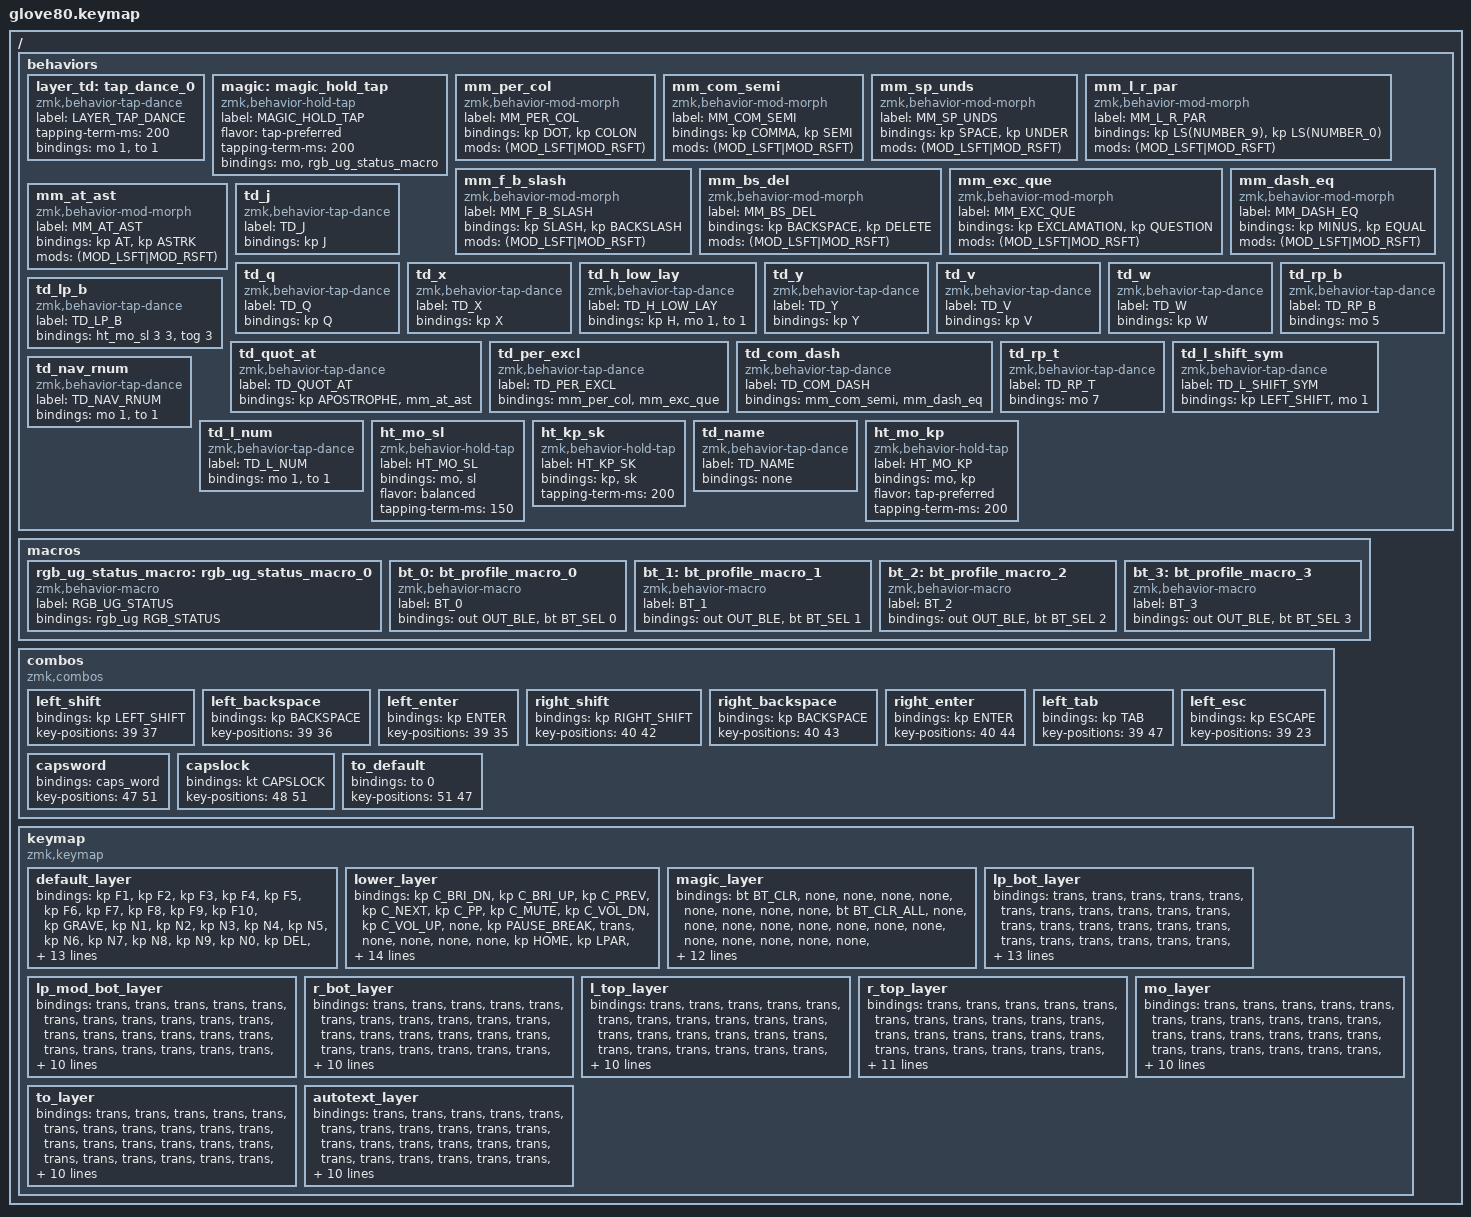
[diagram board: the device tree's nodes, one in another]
/*
 * Copyright (c) 2020 The ZMK Contributors
 *
 * SPDX-License-Identifier: MIT
 */

#include <behaviors.dtsi>
#include <dt-bindings/zmk/bt.h>
#include <dt-bindings/zmk/keys.h>
#include <dt-bindings/zmk/keys.h>
#include <dt-bindings/zmk/outputs.h>
#include <dt-bindings/zmk/rgb.h>

#define HYPER LC(LS(LG(LALT)))

// layers

#define DEFAULT 0
#define LOWER 1
#define MAGIC 2
#define FACTORY_TEST 3

/ {
    behaviors {
        // For the "layer" key, it'd nice to be able to use it as either a shift or a toggle.
        // Configure it as a tap dance, so the first tap (or hold) is a &mo and the second tap is a &to

        layer_td: tap_dance_0 {
            compatible = "zmk,behavior-tap-dance";
            label = "LAYER_TAP_DANCE";
            #binding-cells = <0>;
            tapping-term-ms = <200>;
            bindings = <&mo 1>, <&to 1>;
        };

        magic: magic_hold_tap {
            compatible = "zmk,behavior-hold-tap";
            label = "MAGIC_HOLD_TAP";
            #binding-cells = <2>;
            flavor = "tap-preferred";
            tapping-term-ms = <200>;
            bindings = <&mo>, <&rgb_ug_status_macro>;
        };

        mm_per_col: mm_per_col {
            compatible = "zmk,behavior-mod-morph";
            label = "MM_PER_COL";
            bindings = <&kp DOT>, <&kp COLON>;

            #binding-cells = <0>;
            mods = <(MOD_LSFT|MOD_RSFT)>;
        };

        mm_com_semi: mm_com_semi {
            compatible = "zmk,behavior-mod-morph";
            label = "MM_COM_SEMI";
            bindings = <&kp COMMA>, <&kp SEMI>;

            #binding-cells = <0>;
            mods = <(MOD_LSFT|MOD_RSFT)>;
        };

        mm_sp_unds: mm_sp_unds {
            compatible = "zmk,behavior-mod-morph";
            label = "MM_SP_UNDS";
            bindings = <&kp SPACE>, <&kp UNDER>;

            #binding-cells = <0>;
            mods = <(MOD_LSFT|MOD_RSFT)>;
        };

        mm_l_r_par: mm_l_r_par {
            compatible = "zmk,behavior-mod-morph";
            label = "MM_L_R_PAR";
            bindings = <&kp LS(NUMBER_9)>, <&kp LS(NUMBER_0)>;

            #binding-cells = <0>;
            mods = <(MOD_LSFT|MOD_RSFT)>;
        };

        mm_f_b_slash: mm_f_b_slash {
            compatible = "zmk,behavior-mod-morph";
            label = "MM_F_B_SLASH";
            bindings = <&kp SLASH>, <&kp BACKSLASH>;

            #binding-cells = <0>;
            mods = <(MOD_LSFT|MOD_RSFT)>;
        };

        mm_bs_del: mm_bs_del {
            compatible = "zmk,behavior-mod-morph";
            label = "MM_BS_DEL";
            bindings = <&kp BACKSPACE>, <&kp DELETE>;

            #binding-cells = <0>;
            mods = <(MOD_LSFT|MOD_RSFT)>;
        };

        mm_exc_que: mm_exc_que {
            compatible = "zmk,behavior-mod-morph";
            label = "MM_EXC_QUE";
            bindings = <&kp EXCLAMATION>, <&kp QUESTION>;

            #binding-cells = <0>;
            mods = <(MOD_LSFT|MOD_RSFT)>;
        };

        mm_dash_eq: mm_dash_eq {
            compatible = "zmk,behavior-mod-morph";
            label = "MM_DASH_EQ";
            bindings = <&kp MINUS>, <&kp EQUAL>;

            #binding-cells = <0>;
            mods = <(MOD_LSFT|MOD_RSFT)>;
        };

        mm_at_ast: mm_at_ast {
            compatible = "zmk,behavior-mod-morph";
            label = "MM_AT_AST";
            bindings = <&kp AT>, <&kp ASTRK>;

            #binding-cells = <0>;
            mods = <(MOD_LSFT|MOD_RSFT)>;
        };

        td_j: td_j {
            compatible = "zmk,behavior-tap-dance";
            label = "TD_J";
            #binding-cells = <0>;
            bindings = <&kp J>;
        };

        td_q: td_q {
            compatible = "zmk,behavior-tap-dance";
            label = "TD_Q";
            #binding-cells = <0>;
            bindings = <&kp Q>;
        };

        td_x: td_x {
            compatible = "zmk,behavior-tap-dance";
            label = "TD_X";
            #binding-cells = <0>;
            bindings = <&kp X>;
        };

        td_h_low_lay: td_h_low_lay {
            compatible = "zmk,behavior-tap-dance";
            label = "TD_H_LOW_LAY";
            #binding-cells = <0>;
            bindings = <&kp H>, <&mo 1>, <&to 1>;
        };

        td_y: td_y {
            compatible = "zmk,behavior-tap-dance";
            label = "TD_Y";
            #binding-cells = <0>;
            bindings = <&kp Y>;
        };

        td_v: td_v {
            compatible = "zmk,behavior-tap-dance";
            label = "TD_V";
            #binding-cells = <0>;
            bindings = <&kp V>;
        };

        td_w: td_w {
            compatible = "zmk,behavior-tap-dance";
            label = "TD_W";
            #binding-cells = <0>;
            bindings = <&kp W>;
        };

        td_lp_b: td_lp_b {
            compatible = "zmk,behavior-tap-dance";
            label = "TD_LP_B";
            #binding-cells = <0>;
            bindings = <&ht_mo_sl 3 3>, <&tog 3>;
        };

        td_rp_b: td_rp_b {
            compatible = "zmk,behavior-tap-dance";
            label = "TD_RP_B";
            #binding-cells = <0>;
            bindings = <&mo 5>;
        };

        td_quot_at: td_quot_at {
            compatible = "zmk,behavior-tap-dance";
            label = "TD_QUOT_AT";
            #binding-cells = <0>;
            bindings = <&kp APOSTROPHE>, <&mm_at_ast>;
        };

        td_per_excl: td_per_excl {
            compatible = "zmk,behavior-tap-dance";
            label = "TD_PER_EXCL";
            #binding-cells = <0>;
            bindings = <&mm_per_col>, <&mm_exc_que>;
        };

        td_com_dash: td_com_dash {
            compatible = "zmk,behavior-tap-dance";
            label = "TD_COM_DASH";
            #binding-cells = <0>;
            bindings = <&mm_com_semi>, <&mm_dash_eq>;
        };

        td_rp_t: td_rp_t {
            compatible = "zmk,behavior-tap-dance";
            label = "TD_RP_T";
            #binding-cells = <0>;
            bindings = <&mo 7>;
        };

        td_l_shift_sym: td_l_shift_sym {
            compatible = "zmk,behavior-tap-dance";
            label = "TD_L_SHIFT_SYM";
            #binding-cells = <0>;
            bindings = <&kp LEFT_SHIFT>, <&mo 1>;
        };

        td_nav_rnum: td_nav_rnum {
            compatible = "zmk,behavior-tap-dance";
            label = "TD_NAV_RNUM";
            #binding-cells = <0>;
            bindings = <&mo 1>, <&to 1>;
        };

        td_l_num: td_l_num {
            compatible = "zmk,behavior-tap-dance";
            label = "TD_L_NUM";
            #binding-cells = <0>;
            bindings = <&mo 1>, <&to 1>;
        };

        ht_mo_sl: ht_mo_sl {
            compatible = "zmk,behavior-hold-tap";
            label = "HT_MO_SL";
            bindings = <&mo>, <&sl>;

            #binding-cells = <2>;
            flavor = "balanced";
            tapping-term-ms = <150>;
        };

        ht_kp_sk: ht_kp_sk {
            compatible = "zmk,behavior-hold-tap";
            label = "HT_KP_SK";
            bindings = <&kp>, <&sk>;

            #binding-cells = <2>;
            tapping-term-ms = <200>;
        };

        td_name: td_name {
            compatible = "zmk,behavior-tap-dance";
            label = "TD_NAME";
            #binding-cells = <0>;
            bindings = <&none>;
        };

        ht_mo_kp: ht_mo_kp {
            compatible = "zmk,behavior-hold-tap";
            label = "HT_MO_KP";
            bindings = <&mo>, <&kp>;

            #binding-cells = <2>;
            flavor = "tap-preferred";
            tapping-term-ms = <200>;
        };
    };

    macros {
        rgb_ug_status_macro: rgb_ug_status_macro_0 {
            label = "RGB_UG_STATUS";
            compatible = "zmk,behavior-macro";
            #binding-cells = <0>;
            bindings = <&rgb_ug RGB_STATUS>;
        };

        bt_0: bt_profile_macro_0 {
            label = "BT_0";
            compatible = "zmk,behavior-macro";
            #binding-cells = <0>;
            bindings = <&out OUT_BLE &bt BT_SEL 0>;
        };

        bt_1: bt_profile_macro_1 {
            label = "BT_1";
            compatible = "zmk,behavior-macro";
            #binding-cells = <0>;
            bindings = <&out OUT_BLE &bt BT_SEL 1>;
        };

        bt_2: bt_profile_macro_2 {
            label = "BT_2";
            compatible = "zmk,behavior-macro";
            #binding-cells = <0>;
            bindings = <&out OUT_BLE &bt BT_SEL 2>;
        };

        bt_3: bt_profile_macro_3 {
            label = "BT_3";
            compatible = "zmk,behavior-macro";
            #binding-cells = <0>;
            bindings = <&out OUT_BLE &bt BT_SEL 3>;
        };
    };

    combos {
        compatible = "zmk,combos";

        left_shift {
            bindings = <&kp LEFT_SHIFT>;
            key-positions = <39 37>;
        };

        left_backspace {
            bindings = <&kp BACKSPACE>;
            key-positions = <39 36>;
        };

        left_enter {
            bindings = <&kp ENTER>;
            key-positions = <39 35>;
        };

        right_shift {
            bindings = <&kp RIGHT_SHIFT>;
            key-positions = <40 42>;
        };

        right_backspace {
            bindings = <&kp BACKSPACE>;
            key-positions = <40 43>;
        };

        right_enter {
            bindings = <&kp ENTER>;
            key-positions = <40 44>;
        };

        left_tab {
            bindings = <&kp TAB>;
            key-positions = <39 47>;
        };

        left_esc {
            bindings = <&kp ESCAPE>;
            key-positions = <39 23>;
        };

        capsword {
            bindings = <&caps_word>;
            key-positions = <47 51>;
        };

        capslock {
            bindings = <&kt CAPSLOCK>;
            key-positions = <48 51>;
        };

        to_default {
            bindings = <&to 0>;
            key-positions = <51 47>;
        };
    };

    keymap {
        compatible = "zmk,keymap";

        default_layer {
            // ---------------------------------------------------------------------------------------------------------------------------------
            // |  F1   |  F2 |  F3 |  F4  |  F5  |                                                               |  F6   |  F7   |  F8  |   F9  |  F10 |
            // |  =    |  1  |  2  |  3   |  4   |  5   |                                                 |  6   |   7   |   8   |  9   |   0   |   -  |
            // |  TAB  |  Q  |  W  |  E   |  R   |  T   |                                                 |  Y   |   U   |   I   |  O   |   P   |   \  |
            // |  ESC  |  A  |  S  |  D   |  F   |  G   |                                                 |  H   |   J   |   K   |  L   |   ;   |   '  |
            // |   `   |  Z  |  X  |  C   |  V   |  B   | LSHFT | LCTRL | LOWER | | LGUI  | RCTRL | RSHFT |  N   |   M   |   ,   |  .   |   /   | PGUP |
            // | MAGIC | HOME| END | LEFT | RIGHT|      | BSPC  | DEL   | LALT  | | RALT  | RET   | SPACE |      |  UP   | DOWN  |  [   |   ]   | PGDN |

            bindings = <
&kp F1            &kp F2          &kp F3        &kp F4  &kp F5                                                                                                           &kp F6       &kp F7   &kp F8    &kp F9                    &kp F10
&kp GRAVE         &kp N1          &kp N2        &kp N3  &kp N4       &kp N5                                                                                &kp N6        &kp N7       &kp N8   &kp N9    &kp N0                    &kp DEL
&kp TAB           &ht_mo_kp 10 Q  &kp W         &kp M   &kp B        &kp J                                                                                 &kp SQT       &kp Z        &kp Y    &kp K     &ht_mo_kp 6 C_PLAY_PAUSE  &kp BSPC
&kp ESC           &kp R           &kp S         &kp T   &kp N        &kp V                                                                                 &mm_per_col   &kp A        &kp E    &kp D     &kp I                     &kp RET
&kp LEFT_CONTROL  &td_lp_b        &kp C         &kp G   &kp F        &kp X   &td_l_shift_sym  &td_nav_rnum  &kp SPACE  &kp SPACE  &kp SPACE   &kp RSHFT    &mm_com_semi  &kp O        &kp U    &kp P     &td_rp_b                  &kp RCTRL
&magic 2 0        &kp LALT        &kp LEFT_WIN  &to 0   &key_repeat          &td_h_low_lay    &kp L         &kp SPACE  &kp SPACE  &mm_bs_del  &mm_sp_unds                &key_repeat  &kt INS  &kp RGUI  &kp RALT                  &kp SPACE
            >;
        };

        lower_layer {
            bindings = <
&kp C_BRI_DN  &kp C_BRI_UP  &kp C_PREV  &kp C_NEXT  &kp C_PP                                                                         &kp C_MUTE  &kp C_VOL_DN  &kp C_VOL_UP   &none            &kp PAUSE_BREAK
&trans        &none         &none       &none       &none      &kp HOME                                                   &kp LPAR   &kp KP_NUM  &kp KP_EQUAL  &kp KP_DIVIDE  &kp KP_MULTIPLY  &kp PSCRN
&trans        &none         &none       &kp UP      &none      &kp END                                                    &kp RPAR   &kp KP_N7   &kp KP_N8     &kp KP_N9      &kp KP_MINUS     &kp SLCK
&trans        &none         &kp LEFT    &kp DOWN    &kp RIGHT  &kp PG_UP                                                  &kp PRCNT  &kp KP_N4   &kp KP_N5     &kp KP_N6      &kp KP_PLUS      &none
&trans        &kp K_CMENU   &none       &kp F11     &kp F12    &kp PG_DN  &trans  &trans  &to 0   &trans  &trans  &trans  &kp COMMA  &kp KP_N1   &kp KP_N2     &kp KP_N3      &kp KP_ENTER     &trans
&trans        &kp CAPS      &kp INS     &kp F11     &kp F12               &trans  &trans  &trans  &trans  &trans  &trans             &kp KP_N0   &kp KP_N0     &kp KP_DOT     &kp KP_ENTER     &trans
            >;
        };

        magic_layer {
            bindings = <
&bt BT_CLR   &none            &none            &none            &none                                                                                     &none  &none  &none  &none  &bt BT_CLR_ALL
&none        &none            &none            &none            &none            &none                                                             &none  &none  &none  &none  &none  &none
&none        &rgb_ug RGB_SPI  &rgb_ug RGB_SAI  &rgb_ug RGB_HUI  &rgb_ug RGB_BRI  &rgb_ug RGB_TOG                                                   &none  &none  &none  &none  &none  &none
&bootloader  &rgb_ug RGB_SPD  &rgb_ug RGB_SAD  &rgb_ug RGB_HUD  &rgb_ug RGB_BRD  &rgb_ug RGB_EFF                                                   &none  &none  &none  &none  &none  &bootloader
&sys_reset   &none            &none            &none            &none            &none            &bt_2  &bt_3  &none         &none  &none  &none  &none  &none  &none  &none  &none  &sys_reset
&none        &none            &none            &none            &none                             &bt_0  &bt_1  &out OUT_USB  &none  &none  &none         &none  &none  &none  &none  &to 0
            >;
        };

        lp_bot_layer {
            bindings = <
&trans  &trans  &trans                 &trans     &trans                                                                                           &trans        &trans        &trans        &trans        &trans
&trans  &trans  &trans                 &trans     &trans       &trans                                                               &trans         &trans        &trans        &trans        &trans        &trans
&trans  &trans  &trans                 &trans     &trans       &trans                                                               &kp LS(QMARK)  &kp LS(EXCL)  &kp LBKT      &kp RBKT      &kp GRAVE     &trans
&trans  &trans  &kp A                  &kp LC(L)  &kp K_COPY   &trans                                                               &kp MINUS      &kp EQUAL     &kp LS(LPAR)  &kp LS(RPAR)  &kp LS(AT)    &trans
&trans  &tog 3  &ht_kp_sk LSHFT LSHFT  &sl 4      &kp K_PASTE  &trans  &trans     &trans  &trans  &trans        &trans    &trans    &kp LS(AMPS)   &kp LS(PLUS)  &kp LS(LT)    &kp LS(GT)    &kp LS(STAR)  &trans
&trans  &trans  &trans                 &trans     &trans               &kp LC(Z)  &trans  &trans  &kp LS(PIPE)  &kp FSLH  &kp BSLH                 &trans        &trans        &trans        &trans        &trans
            >;
        };

        lp_mod_bot_layer {
            bindings = <
&trans  &trans  &trans  &trans  &trans                                                                  &trans  &trans  &trans  &trans  &trans
&trans  &trans  &trans  &trans  &trans  &trans                                                  &trans  &trans  &trans  &trans  &trans  &trans
&trans  &trans  &trans  &trans  &trans  &trans                                                  &trans  &trans  &trans  &trans  &trans  &trans
&trans  &trans  &trans  &trans  &trans  &trans                                                  &trans  &trans  &trans  &trans  &trans  &trans
&trans  &trans  &trans  &trans  &trans  &trans  &trans  &trans  &trans  &trans  &trans  &trans  &trans  &trans  &trans  &trans  &trans  &trans
&trans  &trans  &trans  &trans  &trans          &trans  &trans  &trans  &trans  &trans  &trans          &trans  &trans  &trans  &trans  &trans
            >;
        };

        r_bot_layer {
            bindings = <
&trans  &trans  &trans  &trans  &trans                                                                  &trans  &trans  &trans  &trans  &trans
&trans  &trans  &trans  &trans  &trans  &trans                                                  &trans  &trans  &trans  &trans  &trans  &trans
&trans  &trans  &trans  &trans  &trans  &trans                                                  &trans  &trans  &trans  &trans  &trans  &trans
&trans  &trans  &trans  &trans  &trans  &trans                                                  &trans  &trans  &trans  &trans  &trans  &trans
&trans  &trans  &trans  &trans  &trans  &trans  &trans  &trans  &trans  &trans  &trans  &trans  &trans  &trans  &trans  &trans  &trans  &trans
&trans  &trans  &trans  &trans  &trans          &trans  &trans  &trans  &trans  &trans  &trans          &trans  &trans  &trans  &trans  &trans
            >;
        };

        l_top_layer {
            bindings = <
&trans  &trans  &trans  &trans  &trans                                                                  &trans  &trans  &trans  &trans  &trans
&trans  &trans  &trans  &trans  &trans  &trans                                                  &trans  &trans  &trans  &trans  &trans  &trans
&trans  &trans  &trans  &trans  &trans  &trans                                                  &trans  &trans  &trans  &trans  &trans  &trans
&trans  &trans  &trans  &trans  &trans  &trans                                                  &trans  &trans  &trans  &trans  &trans  &trans
&trans  &trans  &trans  &trans  &trans  &trans  &trans  &trans  &trans  &trans  &trans  &trans  &trans  &trans  &trans  &trans  &trans  &trans
&trans  &trans  &trans  &trans  &trans          &trans  &trans  &trans  &trans  &trans  &trans          &trans  &trans  &trans  &trans  &trans
            >;
        };

        r_top_layer {
            bindings = <
&trans  &trans  &trans  &trans  &trans                                                                  &trans          &trans           &trans           &trans  &trans
&trans  &trans  &trans  &trans  &trans  &trans                                                  &trans  &trans          &trans           &trans           &trans  &trans
&trans  &trans  &trans  &trans  &trans  &trans                                                  &trans  &kp C_VOL_DN    &kp PRINTSCREEN  &kp C_VOLUME_UP  &trans  &trans
&trans  &trans  &trans  &trans  &trans  &trans                                                  &trans  &kp C_PREVIOUS  &kp C_NEXT       &trans           &trans  &trans
&trans  &trans  &trans  &trans  &trans  &trans  &trans  &trans  &trans  &trans  &trans  &trans  &trans  &trans          &trans           &trans           &trans  &trans
&trans  &trans  &trans  &trans  &trans          &trans  &trans  &trans  &trans  &trans  &trans          &trans          &trans           &trans           &trans  &trans
            >;
        };

        mo_layer {
            bindings = <
&trans  &trans  &trans  &trans  &trans                                                                  &trans  &trans  &trans  &trans  &trans
&trans  &trans  &trans  &trans  &trans  &trans                                                  &trans  &trans  &trans  &trans  &trans  &trans
&trans  &trans  &trans  &trans  &trans  &trans                                                  &trans  &trans  &trans  &trans  &trans  &trans
&trans  &trans  &trans  &trans  &trans  &trans                                                  &trans  &trans  &trans  &trans  &trans  &trans
&trans  &trans  &trans  &trans  &trans  &trans  &trans  &trans  &trans  &trans  &trans  &trans  &trans  &trans  &trans  &trans  &trans  &trans
&trans  &trans  &trans  &trans  &trans          &trans  &trans  &trans  &trans  &trans  &trans          &trans  &trans  &trans  &trans  &trans
            >;
        };

        to_layer {
            bindings = <
&trans  &trans  &trans  &trans  &trans                                                                  &trans  &trans  &trans  &trans  &trans
&trans  &trans  &trans  &trans  &trans  &trans                                                  &trans  &trans  &trans  &trans  &trans  &trans
&trans  &trans  &trans  &trans  &trans  &trans                                                  &trans  &trans  &trans  &trans  &trans  &trans
&trans  &trans  &trans  &trans  &trans  &trans                                                  &trans  &trans  &trans  &trans  &trans  &trans
&trans  &trans  &trans  &trans  &trans  &trans  &trans  &trans  &trans  &trans  &trans  &trans  &trans  &trans  &trans  &trans  &trans  &trans
&trans  &trans  &trans  &trans  &trans          &trans  &trans  &trans  &trans  &trans  &trans          &trans  &trans  &trans  &trans  &trans
            >;
        };

        autotext_layer {
            bindings = <
&trans  &trans  &trans  &trans  &trans                                                                  &trans  &trans  &trans  &trans  &trans
&trans  &trans  &trans  &trans  &trans  &trans                                                  &trans  &trans  &trans  &trans  &trans  &trans
&trans  &trans  &trans  &trans  &trans  &trans                                                  &trans  &trans  &trans  &trans  &trans  &trans
&trans  &trans  &trans  &trans  &trans  &trans                                                  &trans  &trans  &trans  &trans  &trans  &trans
&trans  &trans  &trans  &trans  &trans  &trans  &trans  &trans  &trans  &trans  &trans  &trans  &trans  &trans  &trans  &trans  &trans  &trans
&trans  &trans  &trans  &trans  &trans          &trans  &trans  &trans  &trans  &trans  &trans          &trans  &trans  &trans  &trans  &trans
            >;
        };
    };
};
